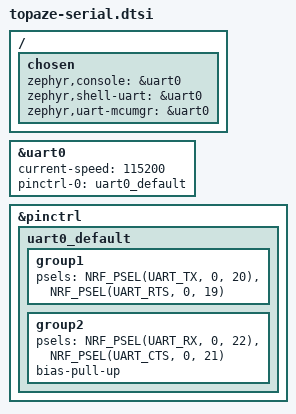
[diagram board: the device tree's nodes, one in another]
/* ============================================================
 * This file is the overlay DTS for topaze that define the UARTS
 *
 * We describe here the peripherals configuration, and so on...
 *
 * l.heywang
 * 19/02/2025
 *
 * ============================================================
 */

// ============================================================
// UARTS and PINCTRL
// ============================================================
// Enable UART drivers with defined settings
&uart0 {
    status = "okay";
    current-speed = <115200>;
    pinctrl-0 = <&uart0_default>;
    pinctrl-names = "default";
};

// We're using here default pins for UART0 and 1, to match the DK
// Sensors are bound to the UART 2 and 3
&pinctrl {
    uart0_default: uart0_default {
		group1 {
			psels = <NRF_PSEL(UART_TX, 0, 20)>,
				    <NRF_PSEL(UART_RTS, 0, 19)>;
		};
		group2 {
			psels = <NRF_PSEL(UART_RX, 0, 22)>,
				    <NRF_PSEL(UART_CTS, 0, 21)>;
			bias-pull-up;
		};
	};
};

// Configure the console output as UART0.
/ {
    chosen {
        zephyr,console = &uart0;
        zephyr,shell-uart = &uart0;
		zephyr,uart-mcumgr = &uart0;
    };
};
